# CORTEX_M7_SCS register map
Registers are 32-bit, write-only, no defined reset value unless marked. A register's access mark holds for its fields unless they carry their own. Offsets are from the block's base; lines under a group give offsets from that group; [hi:lo] are bit positions; {n}, {i} and the like mark numbered series; 'fields as' and 'values as' point back to an identical list; <NAME> marks a mode.

## Memory map
0xE000E100 NVIC
0xE000E400 NVIC_IPR
0xE000ED00 SCB

## NVIC
Base 0xE000E100
{0x0+4i} ISER{i} (i=0..7)
  [31:0] SETENA write-1-sets
{0x100+4i} ISPR{i} (i=0..7)
  [31:0] SETPEND write-1-sets

## NVIC_IPR
Base 0xE000E400
{0x0+i} IP{i} (i=0..149) 8-bit rw
  [7:0] PRI

## SCB
Base 0xE000ED00
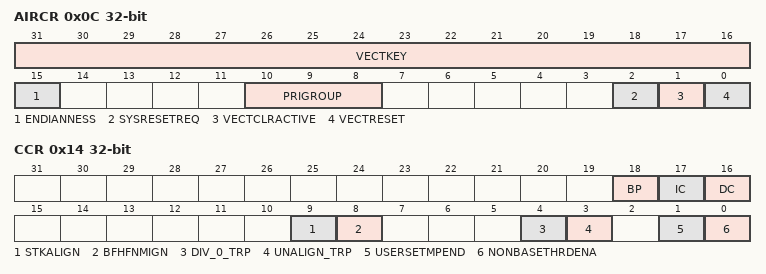
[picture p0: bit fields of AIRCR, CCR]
0x0C AIRCR rw
  [31:16] VECTKEY, [15] ENDIANNESS ro, [10:8] PRIGROUP, [2] SYSRESETREQ, [1] VECTCLRACTIVE, [0] VECTRESET
0x14 CCR rw
  [18] BP, [17] IC, [16] DC, [9] STKALIGN, [8] BFHFNMIGN, [4] DIV_0_TRP, [3] UNALIGN_TRP, [1] USERSETMPEND, [0] NONBASETHRDENA
0x25C DCIMVAC
  [31:0] ADDRESS
